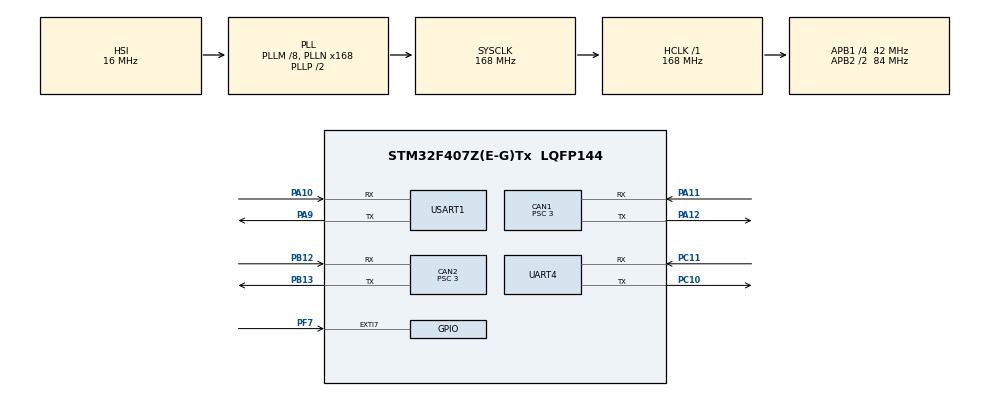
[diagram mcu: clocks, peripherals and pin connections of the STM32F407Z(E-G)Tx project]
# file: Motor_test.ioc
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CAN1.ABOM=ENABLE
CAN1.BS1=CAN_BS1_9TQ
CAN1.BS2=CAN_BS2_4TQ
CAN1.CalculateBaudRate=1000000
CAN1.CalculateTimeBit=1000
CAN1.CalculateTimeQuantum=71.42857142857143
CAN1.Prescaler=3
CAN2.ABOM=ENABLE
CAN2.BS1=CAN_BS1_9TQ
CAN2.BS2=CAN_BS2_4TQ
CAN2.CalculateBaudRate=1000000
CAN2.CalculateTimeBit=1000
CAN2.CalculateTimeQuantum=71.42857142857143
CAN2.Prescaler=3
FREERTOS.Tasks01=Motor,24,512,Motor_task,Default,NULL,Dynamic,NULL,NULL;User,8,512,User_task,Default,NULL,Dynamic,NULL,NULL
Mcu.Family=STM32F4
Mcu.Name=STM32F407Z(E-G)Tx
Mcu.Package=LQFP144
NVIC.CAN1_RX0_IRQn=true\:5\:0\:false\:false\:true\:true\:true\:true\:true
NVIC.CAN2_RX0_IRQn=true\:5\:0\:false\:false\:true\:true\:true\:true\:true
NVIC.EXTI9_5_IRQn=true\:0\:0\:false\:false\:true\:false\:true\:true\:true
NVIC.PriorityGroup=NVIC_PRIORITYGROUP_4
NVIC.TIM2_IRQn=true\:0\:0\:false\:false\:true\:false\:true\:true\:true
NVIC.TIM3_IRQn=true\:15\:0\:false\:false\:true\:false\:false\:true\:true
NVIC.TimeBase=TIM3_IRQn
NVIC.TimeBaseIP=TIM3
NVIC.UART4_IRQn=true\:0\:0\:false\:false\:true\:false\:true\:true\:true
NVIC.USART1_IRQn=true\:5\:0\:false\:false\:true\:true\:true\:true\:true
PA10.Mode=Asynchronous
PA10.Signal=USART1_RX
PA11.Mode=CAN_Activate
PA11.Signal=CAN1_RX
PA12.Mode=CAN_Activate
PA12.Signal=CAN1_TX
PA13.Mode=Serial_Wire
PA13.Signal=SYS_JTMS-SWDIO
PA14.Mode=Serial_Wire
PA14.Signal=SYS_JTCK-SWCLK
PA9.Mode=Asynchronous
PA9.Signal=USART1_TX
PB12.Mode=CAN_Activate
PB12.Signal=CAN2_RX
PB13.Mode=CAN_Activate
PB13.Signal=CAN2_TX
PC10.Mode=Asynchronous
PC10.Signal=UART4_TX
PC11.Mode=Asynchronous
PC11.Signal=UART4_RX
PC14-OSC32_IN.Mode=LSE-External-Oscillator
PC14-OSC32_IN.Signal=RCC_OSC32_IN
PC15-OSC32_OUT.Mode=LSE-External-Oscillator
PC15-OSC32_OUT.Signal=RCC_OSC32_OUT
PF7.Signal=GPXTI7
PH0-OSC_IN.Mode=HSE-External-Oscillator
PH0-OSC_IN.Signal=RCC_OSC_IN
PH1-OSC_OUT.Mode=HSE-External-Oscillator
PH1-OSC_OUT.Signal=RCC_OSC_OUT
ProjectManager.HeapSize=0x200
ProjectManager.StackSize=0x400
ProjectManager.TargetToolchain=MDK-ARM V5.32
RCC.48MHZClocksFreq_Value=84000000
RCC.AHBFreq_Value=168000000
RCC.APB1CLKDivider=RCC_HCLK_DIV4
RCC.APB1Freq_Value=42000000
RCC.APB1TimFreq_Value=84000000
RCC.APB2CLKDivider=RCC_HCLK_DIV2
RCC.APB2Freq_Value=84000000
RCC.APB2TimFreq_Value=168000000
RCC.CortexFreq_Value=168000000
RCC.HCLKFreq_Value=168000000
RCC.HSE_VALUE=25000000
RCC.HSI_VALUE=16000000
RCC.PLLM=8
RCC.PLLN=168
RCC.SYSCLKFreq_VALUE=168000000
RCC.SYSCLKSource=RCC_SYSCLKSOURCE_PLLCLK
RCC.VCOOutputFreq_Value=336000000
TIM2.Period=100000
TIM2.Prescaler=83
UART4.VirtualMode=Asynchronous
USART1.VirtualMode=VM_ASYNC
VP_FREERTOS_VS_CMSIS_V2.Mode=CMSIS_V2
VP_SYS_VS_tim3.Mode=TIM3
VP_TIM2_VS_ClockSourceINT.Mode=Internal
board=custom

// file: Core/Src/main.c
/* USER CODE BEGIN Header */
/**
  ******************************************************************************
  * @file           : main.c
  * @brief          : Main program body
  ******************************************************************************
  * @attention
  *
  * Copyright (c) 2024 STMicroelectronics.
  * All rights reserved.
  *
  * This software is licensed under terms that can be found in the LICENSE file
  * in the root directory of this software component.
  * If no LICENSE file comes with this software, it is provided AS-IS.
  *
  ******************************************************************************
  */
/* USER CODE END Header */
#include "main.h"
#include "cmsis_os.h"
#include "can.h"
#include "tim.h"
#include "usart.h"
#include "gpio.h"

void SystemClock_Config(void);
void MX_FREERTOS_Init(void);

int main(void)
{

  /* MCU Configuration--------------------------------------------------------*/

  /* Reset of all peripherals, Initializes the Flash interface and the Systick. */
  HAL_Init();

  /* Configure the system clock */
  SystemClock_Config();

  /* Initialize all configured peripherals */
  MX_GPIO_Init();
  MX_CAN1_Init();
  MX_CAN2_Init();
  MX_TIM2_Init();
  MX_UART4_Init();
  MX_USART1_UART_Init();
  /* USER CODE BEGIN 2 */
  can1motorRealInfo[0].Motor_Type = M_3508;     //初始化电机类型
  pid_param_init(&can1MOTOR_PID_RPM[0], PID_Position, 8192, 1024, 0, 0.5f, 16384, 12.0f, 0.0f, 0.2f);       //初始化速度环pid
  can_filter_init();        //初始化过滤器

  /* USER CODE END 2 */

  /* Init scheduler */
  osKernelInitialize();  /* Call init function for freertos objects (in freertos.c) */
  MX_FREERTOS_Init();

  /* Start scheduler */
  osKernelStart();

  /* We should never get here as control is now taken by the scheduler */
  /* Infinite loop */
  while (1)
  {

  }
}

void SystemClock_Config(void)
{
  RCC_OscInitTypeDef RCC_OscInitStruct = {0};
  RCC_ClkInitTypeDef RCC_ClkInitStruct = {0};

  /** Configure the main internal regulator output voltage
  */
  __HAL_RCC_PWR_CLK_ENABLE();
  __HAL_PWR_VOLTAGESCALING_CONFIG(PWR_REGULATOR_VOLTAGE_SCALE1);

  /** Initializes the RCC Oscillators according to the specified parameters
  * in the RCC_OscInitTypeDef structure.
  */
  RCC_OscInitStruct.OscillatorType = RCC_OSCILLATORTYPE_HSI;
  RCC_OscInitStruct.HSIState = RCC_HSI_ON;
  RCC_OscInitStruct.HSICalibrationValue = RCC_HSICALIBRATION_DEFAULT;
  RCC_OscInitStruct.PLL.PLLState = RCC_PLL_ON;
  RCC_OscInitStruct.PLL.PLLSource = RCC_PLLSOURCE_HSI;
  RCC_OscInitStruct.PLL.PLLM = 8;
  RCC_OscInitStruct.PLL.PLLN = 168;
  RCC_OscInitStruct.PLL.PLLP = RCC_PLLP_DIV2;
  RCC_OscInitStruct.PLL.PLLQ = 4;
  if (HAL_RCC_OscConfig(&RCC_OscInitStruct) != HAL_OK)
  {
    Error_Handler();
  }

  /** Initializes the CPU, AHB and APB buses clocks
  */
  RCC_ClkInitStruct.ClockType = RCC_CLOCKTYPE_HCLK|RCC_CLOCKTYPE_SYSCLK
                              |RCC_CLOCKTYPE_PCLK1|RCC_CLOCKTYPE_PCLK2;
  RCC_ClkInitStruct.SYSCLKSource = RCC_SYSCLKSOURCE_PLLCLK;
  RCC_ClkInitStruct.AHBCLKDivider = RCC_SYSCLK_DIV1;
  RCC_ClkInitStruct.APB1CLKDivider = RCC_HCLK_DIV4;
  RCC_ClkInitStruct.APB2CLKDivider = RCC_HCLK_DIV2;

  if (HAL_RCC_ClockConfig(&RCC_ClkInitStruct, FLASH_LATENCY_5) != HAL_OK)
  {
    Error_Handler();
  }
}

void HAL_TIM_PeriodElapsedCallback(TIM_HandleTypeDef *htim)
{
  if (htim->Instance == TIM3) {
    HAL_IncTick();
  }
}

void Error_Handler(void)
{
  __disable_irq();
  while (1)
  {
  }
}

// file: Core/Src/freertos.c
/* USER CODE BEGIN Header */
/**
  ******************************************************************************
  * File Name          : freertos.c
  * Description        : Code for freertos applications
  ******************************************************************************
  * @attention
  *
  * Copyright (c) 2024 STMicroelectronics.
  * All rights reserved.
  *
  * This software is licensed under terms that can be found in the LICENSE file
  * in the root directory of this software component.
  * If no LICENSE file comes with this software, it is provided AS-IS.
  *
  ******************************************************************************
  */
/* USER CODE END Header */

#include "FreeRTOS.h"
#include "task.h"
#include "main.h"
#include "cmsis_os.h"

/* Definitions for Motor */
osThreadId_t MotorHandle;
const osThreadAttr_t Motor_attributes = {
  .name = "Motor",
  .stack_size = 512 * 4,
  .priority = (osPriority_t) osPriorityNormal,
};
/* Definitions for User */
osThreadId_t UserHandle;
const osThreadAttr_t User_attributes = {
  .name = "User",
  .stack_size = 512 * 4,
  .priority = (osPriority_t) osPriorityLow,
};

void Motor_task(void *argument);
void User_task(void *argument);

void MX_FREERTOS_Init(void); /* (MISRA C 2004 rule 8.1) */

void MX_FREERTOS_Init(void) {

  /* Create the thread(s) */
  /* creation of Motor */
  MotorHandle = osThreadNew(Motor_task, NULL, &Motor_attributes);

  /* creation of User */
  UserHandle = osThreadNew(User_task, NULL, &User_attributes);

}

void Motor_task(void *argument)
{
  /* USER CODE BEGIN Motor_task */
  /* Infinite loop */
  for(;;)
  {
    Motor_Control();        //电机总控
    osDelay(1);
  }
  /* USER CODE END Motor_task */
}

void User_task(void *argument)
{
  /* USER CODE BEGIN User_task */
  /* Infinite loop */
  for(;;)
  {
    Speed_Control(&can1motorRealInfo[0],100);       //电机具体控制
    sent_data(can1motorRealInfo[0].ANGLE,can1motorRealInfo[0].CURRENT,can1motorRealInfo[0].RPM,0);      //向上位机发送数据
    osDelay(10);        //这个可以设置大一点。
  }
  /* USER CODE END User_task */
}
